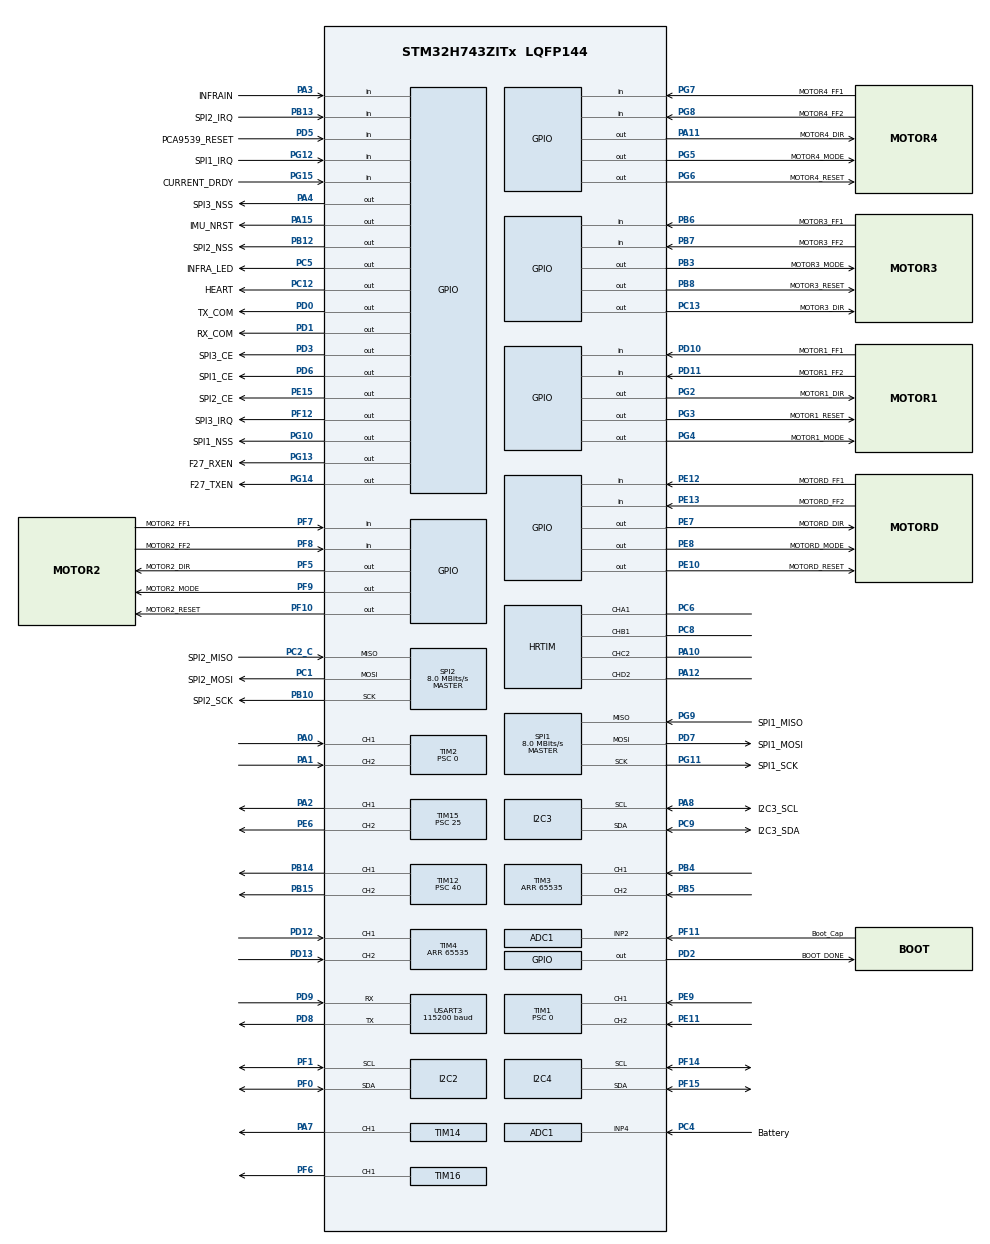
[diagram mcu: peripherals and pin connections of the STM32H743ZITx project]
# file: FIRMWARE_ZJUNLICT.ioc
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ADC1.Channel-0\#ChannelRegularConversion=ADC_CHANNEL_4
ADC1.Channel-1\#ChannelRegularConversion=ADC_CHANNEL_2
ADC1.ClockPrescaler=ADC_CLOCK_ASYNC_DIV2
ADC1.ContinuousConvMode=ENABLE
ADC1.ConversionDataManagement=ADC_CONVERSIONDATA_DMA_CIRCULAR
ADC1.EOCSelection=ADC_EOC_SINGLE_CONV
ADC1.LeftBitShift=ADC_LEFTBITSHIFT_NONE
ADC1.NbrOfConversion=2
ADC1.NbrOfConversionFlag=1
ADC1.OffsetNumber-1\#ChannelRegularConversion=ADC_OFFSET_NONE
ADC1.Overrun=ADC_OVR_DATA_OVERWRITTEN
ADC1.Rank-1\#ChannelRegularConversion=2
ADC1.SamplingTime-0\#ChannelRegularConversion=ADC_SAMPLETIME_2CYCLES_5
ADC1.SamplingTime-1\#ChannelRegularConversion=ADC_SAMPLETIME_1CYCLE_5
ADC1.master=1
CORTEX_M7.CPU_DCache=Disabled
CORTEX_M7.CPU_ICache=Enabled
Dma.ADC1.3.Direction=DMA_PERIPH_TO_MEMORY
Dma.ADC1.3.EventEnable=DISABLE
Dma.ADC1.3.FIFOMode=DMA_FIFOMODE_DISABLE
Dma.ADC1.3.Instance=DMA1_Stream2
Dma.ADC1.3.MemDataAlignment=DMA_MDATAALIGN_HALFWORD
Dma.ADC1.3.MemInc=DMA_MINC_ENABLE
Dma.ADC1.3.Mode=DMA_CIRCULAR
Dma.ADC1.3.PeriphDataAlignment=DMA_PDATAALIGN_HALFWORD
Dma.ADC1.3.PeriphInc=DMA_PINC_DISABLE
Dma.ADC1.3.Polarity=HAL_DMAMUX_REQ_GEN_RISING
Dma.ADC1.3.Priority=DMA_PRIORITY_MEDIUM
Dma.ADC1.3.RequestNumber=1
Dma.ADC1.3.SignalID=HAL_DMAMUX1_REQ_GEN_TIM12_TRGO
Dma.ADC1.3.SyncEnable=DISABLE
Dma.ADC1.3.SyncPolarity=HAL_DMAMUX_SYNC_NO_EVENT
Dma.ADC1.3.SyncRequestNumber=1
Dma.ADC1.3.SyncSignalID=NONE
Dma.I2C3_RX.1.Direction=DMA_PERIPH_TO_MEMORY
Dma.I2C3_RX.1.EventEnable=DISABLE
Dma.I2C3_RX.1.FIFOMode=DMA_FIFOMODE_ENABLE
Dma.I2C3_RX.1.FIFOThreshold=DMA_FIFO_THRESHOLD_FULL
Dma.I2C3_RX.1.Instance=DMA1_Stream1
Dma.I2C3_RX.1.MemBurst=DMA_MBURST_SINGLE
Dma.I2C3_RX.1.MemDataAlignment=DMA_MDATAALIGN_BYTE
Dma.I2C3_RX.1.MemInc=DMA_MINC_ENABLE
Dma.I2C3_RX.1.Mode=DMA_NORMAL
Dma.I2C3_RX.1.PeriphBurst=DMA_PBURST_SINGLE
Dma.I2C3_RX.1.PeriphDataAlignment=DMA_PDATAALIGN_BYTE
Dma.I2C3_RX.1.PeriphInc=DMA_PINC_DISABLE
Dma.I2C3_RX.1.Polarity=HAL_DMAMUX_REQ_GEN_RISING
Dma.I2C3_RX.1.Priority=DMA_PRIORITY_LOW
Dma.I2C3_RX.1.RequestNumber=1
Dma.I2C3_RX.1.SignalID=HAL_DMAMUX1_REQ_GEN_TIM12_TRGO
Dma.I2C3_RX.1.SyncEnable=DISABLE
Dma.I2C3_RX.1.SyncPolarity=HAL_DMAMUX_SYNC_NO_EVENT
Dma.I2C3_RX.1.SyncRequestNumber=1
Dma.I2C3_RX.1.SyncSignalID=NONE
Dma.I2C3_TX.0.Direction=DMA_MEMORY_TO_PERIPH
Dma.I2C3_TX.0.EventEnable=DISABLE
Dma.I2C3_TX.0.FIFOMode=DMA_FIFOMODE_ENABLE
Dma.I2C3_TX.0.FIFOThreshold=DMA_FIFO_THRESHOLD_FULL
Dma.I2C3_TX.0.Instance=DMA1_Stream0
Dma.I2C3_TX.0.MemBurst=DMA_MBURST_SINGLE
Dma.I2C3_TX.0.MemDataAlignment=DMA_MDATAALIGN_BYTE
Dma.I2C3_TX.0.MemInc=DMA_MINC_ENABLE
Dma.I2C3_TX.0.Mode=DMA_NORMAL
Dma.I2C3_TX.0.PeriphBurst=DMA_PBURST_SINGLE
Dma.I2C3_TX.0.PeriphDataAlignment=DMA_PDATAALIGN_BYTE
Dma.I2C3_TX.0.PeriphInc=DMA_PINC_DISABLE
Dma.I2C3_TX.0.Polarity=HAL_DMAMUX_REQ_GEN_RISING
Dma.I2C3_TX.0.Priority=DMA_PRIORITY_LOW
Dma.I2C3_TX.0.RequestNumber=1
Dma.I2C3_TX.0.SignalID=HAL_DMAMUX1_REQ_GEN_TIM12_TRGO
Dma.I2C3_TX.0.SyncEnable=DISABLE
Dma.I2C3_TX.0.SyncPolarity=HAL_DMAMUX_SYNC_NO_EVENT
Dma.I2C3_TX.0.SyncRequestNumber=1
Dma.I2C3_TX.0.SyncSignalID=NONE
Dma.Request0=I2C3_TX
Dma.Request1=I2C3_RX
Dma.Request2=USART3_TX
Dma.Request3=ADC1
Dma.Request4=SPI1_RX
Dma.Request5=SPI1_TX
Dma.Request6=SPI2_RX
Dma.Request7=SPI2_TX
Dma.SPI1_RX.4.Direction=DMA_PERIPH_TO_MEMORY
Dma.SPI1_RX.4.EventEnable=DISABLE
Dma.SPI1_RX.4.FIFOMode=DMA_FIFOMODE_ENABLE
Dma.SPI1_RX.4.FIFOThreshold=DMA_FIFO_THRESHOLD_FULL
Dma.SPI1_RX.4.Instance=DMA2_Stream0
Dma.SPI1_RX.4.MemBurst=DMA_MBURST_SINGLE
Dma.SPI1_RX.4.MemDataAlignment=DMA_MDATAALIGN_BYTE
Dma.SPI1_RX.4.MemInc=DMA_MINC_ENABLE
Dma.SPI1_RX.4.Mode=DMA_NORMAL
Dma.SPI1_RX.4.PeriphBurst=DMA_PBURST_SINGLE
Dma.SPI1_RX.4.PeriphDataAlignment=DMA_PDATAALIGN_BYTE
Dma.SPI1_RX.4.PeriphInc=DMA_PINC_DISABLE
Dma.SPI1_RX.4.Polarity=HAL_DMAMUX_REQ_GEN_RISING
Dma.SPI1_RX.4.Priority=DMA_PRIORITY_MEDIUM
Dma.SPI1_RX.4.RequestNumber=1
Dma.SPI1_RX.4.SignalID=HAL_DMAMUX1_REQ_GEN_TIM12_TRGO
Dma.SPI1_RX.4.SyncEnable=DISABLE
Dma.SPI1_RX.4.SyncPolarity=HAL_DMAMUX_SYNC_NO_EVENT
Dma.SPI1_RX.4.SyncRequestNumber=1
Dma.SPI1_RX.4.SyncSignalID=NONE
Dma.SPI1_TX.5.Direction=DMA_MEMORY_TO_PERIPH
Dma.SPI1_TX.5.EventEnable=DISABLE
Dma.SPI1_TX.5.FIFOMode=DMA_FIFOMODE_ENABLE
Dma.SPI1_TX.5.FIFOThreshold=DMA_FIFO_THRESHOLD_FULL
Dma.SPI1_TX.5.Instance=DMA2_Stream1
Dma.SPI1_TX.5.MemBurst=DMA_MBURST_SINGLE
Dma.SPI1_TX.5.MemDataAlignment=DMA_MDATAALIGN_BYTE
Dma.SPI1_TX.5.MemInc=DMA_MINC_ENABLE
Dma.SPI1_TX.5.Mode=DMA_NORMAL
Dma.SPI1_TX.5.PeriphBurst=DMA_PBURST_SINGLE
Dma.SPI1_TX.5.PeriphDataAlignment=DMA_PDATAALIGN_BYTE
Dma.SPI1_TX.5.PeriphInc=DMA_PINC_DISABLE
Dma.SPI1_TX.5.Polarity=HAL_DMAMUX_REQ_GEN_RISING
Dma.SPI1_TX.5.Priority=DMA_PRIORITY_MEDIUM
Dma.SPI1_TX.5.RequestNumber=1
Dma.SPI1_TX.5.SignalID=HAL_DMAMUX1_REQ_GEN_TIM12_TRGO
Dma.SPI1_TX.5.SyncEnable=DISABLE
Dma.SPI1_TX.5.SyncPolarity=HAL_DMAMUX_SYNC_NO_EVENT
Dma.SPI1_TX.5.SyncRequestNumber=1
Dma.SPI1_TX.5.SyncSignalID=NONE
Dma.SPI2_RX.6.Direction=DMA_PERIPH_TO_MEMORY
Dma.SPI2_RX.6.EventEnable=DISABLE
Dma.SPI2_RX.6.FIFOMode=DMA_FIFOMODE_ENABLE
Dma.SPI2_RX.6.FIFOThreshold=DMA_FIFO_THRESHOLD_FULL
Dma.SPI2_RX.6.Instance=DMA1_Stream4
Dma.SPI2_RX.6.MemBurst=DMA_MBURST_SINGLE
Dma.SPI2_RX.6.MemDataAlignment=DMA_MDATAALIGN_BYTE
Dma.SPI2_RX.6.MemInc=DMA_MINC_ENABLE
Dma.SPI2_RX.6.Mode=DMA_NORMAL
Dma.SPI2_RX.6.PeriphBurst=DMA_PBURST_SINGLE
Dma.SPI2_RX.6.PeriphDataAlignment=DMA_PDATAALIGN_BYTE
Dma.SPI2_RX.6.PeriphInc=DMA_PINC_DISABLE
Dma.SPI2_RX.6.Polarity=HAL_DMAMUX_REQ_GEN_RISING
Dma.SPI2_RX.6.Priority=DMA_PRIORITY_LOW
Dma.SPI2_RX.6.RequestNumber=1
Dma.SPI2_RX.6.SignalID=HAL_DMAMUX1_REQ_GEN_TIM12_TRGO
Dma.SPI2_RX.6.SyncEnable=DISABLE
Dma.SPI2_RX.6.SyncPolarity=HAL_DMAMUX_SYNC_NO_EVENT
Dma.SPI2_RX.6.SyncRequestNumber=1
Dma.SPI2_RX.6.SyncSignalID=HAL_DMAMUX1_SYNC_TIM12_TRGO
Dma.SPI2_TX.7.Direction=DMA_MEMORY_TO_PERIPH
Dma.SPI2_TX.7.EventEnable=DISABLE
Dma.SPI2_TX.7.FIFOMode=DMA_FIFOMODE_ENABLE
Dma.SPI2_TX.7.FIFOThreshold=DMA_FIFO_THRESHOLD_FULL
Dma.SPI2_TX.7.Instance=DMA1_Stream5
Dma.SPI2_TX.7.MemBurst=DMA_MBURST_SINGLE
Dma.SPI2_TX.7.MemDataAlignment=DMA_MDATAALIGN_BYTE
Dma.SPI2_TX.7.MemInc=DMA_MINC_ENABLE
Dma.SPI2_TX.7.Mode=DMA_NORMAL
Dma.SPI2_TX.7.PeriphBurst=DMA_PBURST_SINGLE
Dma.SPI2_TX.7.PeriphDataAlignment=DMA_PDATAALIGN_BYTE
Dma.SPI2_TX.7.PeriphInc=DMA_PINC_DISABLE
Dma.SPI2_TX.7.Polarity=HAL_DMAMUX_REQ_GEN_RISING
Dma.SPI2_TX.7.Priority=DMA_PRIORITY_LOW
Dma.SPI2_TX.7.RequestNumber=1
Dma.SPI2_TX.7.SignalID=HAL_DMAMUX1_REQ_GEN_TIM12_TRGO
Dma.SPI2_TX.7.SyncEnable=DISABLE
Dma.SPI2_TX.7.SyncPolarity=HAL_DMAMUX_SYNC_NO_EVENT
Dma.SPI2_TX.7.SyncRequestNumber=1
Dma.SPI2_TX.7.SyncSignalID=HAL_DMAMUX1_SYNC_TIM12_TRGO
Dma.USART3_TX.2.Direction=DMA_MEMORY_TO_PERIPH
Dma.USART3_TX.2.EventEnable=DISABLE
Dma.USART3_TX.2.FIFOMode=DMA_FIFOMODE_ENABLE
Dma.USART3_TX.2.FIFOThreshold=DMA_FIFO_THRESHOLD_FULL
Dma.USART3_TX.2.Instance=DMA1_Stream3
Dma.USART3_TX.2.MemBurst=DMA_MBURST_SINGLE
Dma.USART3_TX.2.MemDataAlignment=DMA_MDATAALIGN_BYTE
Dma.USART3_TX.2.MemInc=DMA_MINC_ENABLE
Dma.USART3_TX.2.Mode=DMA_NORMAL
Dma.USART3_TX.2.PeriphBurst=DMA_PBURST_SINGLE
Dma.USART3_TX.2.PeriphDataAlignment=DMA_PDATAALIGN_BYTE
Dma.USART3_TX.2.PeriphInc=DMA_PINC_DISABLE
Dma.USART3_TX.2.Polarity=HAL_DMAMUX_REQ_GEN_RISING
Dma.USART3_TX.2.Priority=DMA_PRIORITY_HIGH
Dma.USART3_TX.2.RequestNumber=1
Dma.USART3_TX.2.SignalID=HAL_DMAMUX1_REQ_GEN_TIM12_TRGO
Dma.USART3_TX.2.SyncEnable=DISABLE
Dma.USART3_TX.2.SyncPolarity=HAL_DMAMUX_SYNC_NO_EVENT
Dma.USART3_TX.2.SyncRequestNumber=1
Dma.USART3_TX.2.SyncSignalID=NONE
HRTIM.CompareUnit1-Output_TA1=HRTIM_COMPAREUNIT_1
HRTIM.CompareUnit1-Output_TB1=HRTIM_COMPAREUNIT_1
HRTIM.CompareUnit1-Output_TC2=HRTIM_COMPAREUNIT_1
HRTIM.CompareUnit1-Output_TD2=HRTIM_COMPAREUNIT_1
HRTIM.CompareValue1-Output_TA1=3
HRTIM.CompareValue1-Output_TB1=3
HRTIM.CompareValue1-Output_TC2=3
HRTIM.CompareValue1-Output_TD2=3
HRTIM.Configuration_TC=Waveform
HRTIM.HalfModeEnable-Output_TC2=HRTIM_HALFMODE_DISABLED
HRTIM.NumberResetSource1-Output_TA1=1
HRTIM.NumberResetSource1-Output_TB1=1
HRTIM.NumberResetSource2-Output_TC2=1
HRTIM.NumberResetSource2-Output_TD2=1
HRTIM.NumberSetSource1-Output_TA1=1
HRTIM.NumberSetSource1-Output_TB1=1
HRTIM.NumberSetSource2-Output_TC2=1
HRTIM.NumberSetSource2-Output_TD2=1
HRTIM.Periode_TA=8000
HRTIM.Periode_TB=8000
HRTIM.Periode_TC=8000
HRTIM.Periode_TD=8000
HRTIM.PrescalerRatio_TC=HRTIM_PRESCALERRATIO_DIV1
HRTIM.RepetitionCounter-Output_TC2=0
HRTIM.ResetOutput1_Source1-Output_TA1=HRTIM_OUTPUTRESET_TIMCMP1
HRTIM.ResetOutput1_Source1-Output_TB1=HRTIM_OUTPUTRESET_TIMCMP1
HRTIM.ResetOutput2_Source1-Output_TC2=HRTIM_OUTPUTRESET_TIMCMP1
HRTIM.ResetOutput2_Source1-Output_TD2=HRTIM_OUTPUTRESET_TIMCMP1
HRTIM.SetOutput1_Source1-Output_TA1=HRTIM_OUTPUTSET_TIMPER
HRTIM.SetOutput1_Source1-Output_TB1=HRTIM_OUTPUTSET_TIMPER
HRTIM.SetOutput2_Source1-Output_TC2=HRTIM_OUTPUTSET_TIMPER
HRTIM.SetOutput2_Source1-Output_TD2=HRTIM_OUTPUTSET_TIMPER
I2C2.Timing=0x10C0ECFF
I2C3.Timing=0x10C0ECFF
I2C4.Timing=0x10C0ECFF
Mcu.Family=STM32H7
Mcu.Name=STM32H743ZITx
Mcu.Package=LQFP144
NVIC.ADC_IRQn=true\:0\:0\:false\:false\:true\:true\:true
NVIC.DMA1_Stream0_IRQn=true\:0\:0\:false\:false\:true\:false\:true
NVIC.DMA1_Stream1_IRQn=true\:0\:0\:false\:false\:true\:false\:true
NVIC.DMA1_Stream2_IRQn=true\:0\:0\:false\:false\:true\:false\:true
NVIC.DMA1_Stream3_IRQn=true\:0\:0\:false\:false\:true\:false\:true
NVIC.DMA1_Stream4_IRQn=true\:0\:0\:false\:false\:true\:false\:true
NVIC.DMA1_Stream5_IRQn=true\:0\:0\:false\:false\:true\:false\:true
NVIC.DMA2_Stream0_IRQn=true\:0\:0\:false\:false\:true\:false\:true
NVIC.DMA2_Stream1_IRQn=true\:0\:0\:false\:false\:true\:false\:true
NVIC.PriorityGroup=NVIC_PRIORITYGROUP_4
NVIC.SPI1_IRQn=true\:1\:0\:true\:false\:true\:false\:true
NVIC.SPI2_IRQn=true\:0\:0\:false\:false\:true\:false\:true
NVIC.TIM5_IRQn=true\:2\:0\:true\:false\:true\:true\:true
NVIC.USART3_IRQn=true\:0\:0\:false\:false\:true\:true\:true
PA0.Signal=S_TIM2_CH1
PA1.Signal=S_TIM2_CH2
PA10.Mode=Output_TC2
PA10.Signal=HRTIM_CHC2
PA11.GPIO_Label=MOTOR4_DIR
PA11.GPIO_ModeDefaultOutputPP=GPIO_MODE_OUTPUT_PP
PA11.GPIO_PuPd=GPIO_NOPULL
PA11.GPIO_Speed=GPIO_SPEED_FREQ_LOW
PA11.PinState=GPIO_PIN_RESET
PA11.Signal=GPIO_Output
PA12.Mode=Output_TD2
PA12.Signal=HRTIM_CHD2
PA15\ (JTDI).GPIO_Label=IMU_NRST
PA15\ (JTDI).Signal=GPIO_Output
PA2.Signal=S_TIM15_CH1
PA3.GPIO_Label=INFRAIN
PA3.GPIO_Mode=GPIO_MODE_INPUT
PA3.GPIO_PuPd=GPIO_NOPULL
PA3.Signal=GPIO_Input
PA4.GPIO_Label=SPI3_NSS
PA4.Signal=GPIO_Output
PA7.Signal=S_TIM14_CH1
PA8.GPIO_Label=I2C3_SCL
PA8.GPIO_Mode=GPIO_MODE_AF_OD
PA8.GPIO_PuPd=GPIO_NOPULL
PA8.GPIO_Speed=GPIO_SPEED_FREQ_LOW
PA8.Mode=I2C
PA8.Signal=I2C3_SCL
PB10.GPIO_Label=SPI2_SCK
PB10.Mode=Full_Duplex_Master
PB10.Signal=SPI2_SCK
PB12.GPIO_Label=SPI2_NSS
PB12.GPIO_ModeDefaultOutputPP=GPIO_MODE_OUTPUT_PP
PB12.GPIO_PuPd=GPIO_NOPULL
PB12.GPIO_Speed=GPIO_SPEED_FREQ_LOW
PB12.PinState=GPIO_PIN_RESET
PB12.Signal=GPIO_Output
PB13.GPIO_Label=SPI2_IRQ
PB13.GPIO_Mode=GPIO_MODE_INPUT
PB13.GPIO_PuPd=GPIO_NOPULL
PB13.Signal=GPIO_Input
PB14.Signal=S_TIM12_CH1
PB15.Signal=S_TIM12_CH2
PB2.Signal=SPI3_MOSI
PB3\ (JTDO/TRACESWO).GPIO_Label=MOTOR3_MODE
PB3\ (JTDO/TRACESWO).Signal=GPIO_Output
PB4\ (NJTRST).Signal=S_TIM3_CH1
PB5.Signal=S_TIM3_CH2
PB6.GPIO_Label=MOTOR3_FF1
PB6.GPIO_Mode=GPIO_MODE_INPUT
PB6.GPIO_PuPd=GPIO_NOPULL
PB6.Signal=GPIO_Input
PB7.GPIO_Label=MOTOR3_FF2
PB7.GPIO_Mode=GPIO_MODE_INPUT
PB7.GPIO_PuPd=GPIO_NOPULL
PB7.Signal=GPIO_Input
PB8.GPIO_FM8=__NULL
PB8.GPIO_Label=MOTOR3_RESET
PB8.GPIO_ModeDefaultOutputPP=GPIO_MODE_OUTPUT_PP
PB8.GPIO_PuPd=GPIO_NOPULL
PB8.GPIO_Speed=GPIO_SPEED_FREQ_LOW
PB8.PinState=GPIO_PIN_RESET
PB8.Signal=GPIO_Output
PC1.GPIO_Label=SPI2_MOSI
PC1.Mode=Full_Duplex_Master
PC1.Signal=SPI2_MOSI
PC10.Signal=SPI3_SCK
PC11.Signal=SPI3_MISO
PC12.GPIO_Label=HEART 
PC12.GPIO_ModeDefaultOutputPP=GPIO_MODE_OUTPUT_PP
PC12.GPIO_PuPd=GPIO_NOPULL
PC12.GPIO_Speed=GPIO_SPEED_FREQ_LOW
PC12.PinState=GPIO_PIN_RESET
PC12.Signal=GPIO_Output
PC13.GPIO_Label=MOTOR3_DIR
PC13.GPIO_ModeDefaultOutputPP=GPIO_MODE_OUTPUT_PP
PC13.GPIO_PuPd=GPIO_NOPULL
PC13.GPIO_Speed=GPIO_SPEED_FREQ_LOW
PC13.PinState=GPIO_PIN_RESET
PC13.Signal=GPIO_Output
PC2_C.GPIO_Label=SPI2_MISO
PC2_C.Mode=Full_Duplex_Master
PC2_C.Signal=SPI2_MISO
PC4.GPIO_Label=Battery
PC4.GPIO_Mode=GPIO_MODE_ANALOG
PC4.GPIO_PuPd=GPIO_NOPULL
PC4.Signal=ADCx_INP4
PC5.GPIO_Label=INFRA_LED
PC5.GPIO_ModeDefaultOutputPP=GPIO_MODE_OUTPUT_PP
PC5.GPIO_PuPd=GPIO_NOPULL
PC5.GPIO_Speed=GPIO_SPEED_FREQ_LOW
PC5.PinState=GPIO_PIN_RESET
PC5.Signal=GPIO_Output
PC6.Mode=Output_TA1
PC6.Signal=HRTIM_CHA1
PC8.Mode=Output_TB1
PC8.Signal=HRTIM_CHB1
PC9.GPIO_Label=I2C3_SDA
PC9.GPIO_Mode=GPIO_MODE_AF_OD
PC9.GPIO_PuPd=GPIO_NOPULL
PC9.GPIO_Speed=GPIO_SPEED_FREQ_LOW
PC9.Mode=I2C
PC9.Signal=I2C3_SDA
PD0.GPIO_Label=TX_COM
PD0.Signal=GPIO_Output
PD1.GPIO_Label=RX_COM
PD1.Signal=GPIO_Output
PD10.GPIO_Label=MOTOR1_FF1
PD10.GPIO_Mode=GPIO_MODE_INPUT
PD10.GPIO_PuPd=GPIO_NOPULL
PD10.Signal=GPIO_Input
PD11.GPIO_Label=MOTOR1_FF2
PD11.GPIO_Mode=GPIO_MODE_INPUT
PD11.GPIO_PuPd=GPIO_NOPULL
PD11.Signal=GPIO_Input
PD12.Signal=S_TIM4_CH1
PD13.Signal=S_TIM4_CH2
PD14.Signal=UART8_CTS
PD15.Signal=UART8_RTS
PD2.GPIO_Label=BOOT_DONE
PD2.Signal=GPIO_Output
PD3.GPIO_Label=SPI3_CE
PD3.Signal=GPIO_Output
PD5.GPIO_Label=PCA9539_RESET
PD5.Signal=GPIO_Input
PD6.GPIO_Label=SPI1_CE
PD6.GPIO_ModeDefaultOutputPP=GPIO_MODE_OUTPUT_PP
PD6.GPIO_PuPd=GPIO_NOPULL
PD6.GPIO_Speed=GPIO_SPEED_FREQ_LOW
PD6.PinState=GPIO_PIN_RESET
PD6.Signal=GPIO_Output
PD7.GPIO_Label=SPI1_MOSI
PD7.Mode=Full_Duplex_Master
PD7.Signal=SPI1_MOSI
PD8.Mode=Asynchronous
PD8.Signal=USART3_TX
PD9.Mode=Asynchronous
PD9.Signal=USART3_RX
PE10.GPIO_Label=MOTORD_RESET
PE10.GPIO_ModeDefaultOutputPP=GPIO_MODE_OUTPUT_PP
PE10.GPIO_PuPd=GPIO_NOPULL
PE10.GPIO_Speed=GPIO_SPEED_FREQ_LOW
PE10.PinState=GPIO_PIN_RESET
PE10.Signal=GPIO_Output
PE11.Signal=S_TIM1_CH2
PE12.GPIO_Label=MOTORD_FF1
PE12.GPIO_Mode=GPIO_MODE_INPUT
PE12.GPIO_PuPd=GPIO_NOPULL
PE12.Signal=GPIO_Input
PE13.GPIO_Label=MOTORD_FF2
PE13.GPIO_Mode=GPIO_MODE_INPUT
PE13.GPIO_PuPd=GPIO_NOPULL
PE13.Signal=GPIO_Input
PE15.GPIO_Label=SPI2_CE
PE15.GPIO_ModeDefaultOutputPP=GPIO_MODE_OUTPUT_PP
PE15.GPIO_PuPd=GPIO_NOPULL
PE15.GPIO_Speed=GPIO_SPEED_FREQ_LOW
PE15.PinState=GPIO_PIN_RESET
PE15.Signal=GPIO_Output
PE6.Signal=S_TIM15_CH2
PE7.GPIO_Label=MOTORD_DIR
PE7.GPIO_ModeDefaultOutputPP=GPIO_MODE_OUTPUT_PP
PE7.GPIO_PuPd=GPIO_NOPULL
PE7.GPIO_Speed=GPIO_SPEED_FREQ_LOW
PE7.PinState=GPIO_PIN_RESET
PE7.Signal=GPIO_Output
PE8.GPIO_Label=MOTORD_MODE
PE8.GPIO_ModeDefaultOutputPP=GPIO_MODE_OUTPUT_PP
PE8.GPIO_PuPd=GPIO_NOPULL
PE8.GPIO_Speed=GPIO_SPEED_FREQ_LOW
PE8.PinState=GPIO_PIN_RESET
PE8.Signal=GPIO_Output
PE9.Signal=S_TIM1_CH1
PF0.Mode=I2C
PF0.Signal=I2C2_SDA
PF1.Mode=I2C
PF1.Signal=I2C2_SCL
PF10.GPIO_Label=MOTOR2_RESET 
PF10.GPIO_ModeDefaultOutputPP=GPIO_MODE_OUTPUT_PP
PF10.GPIO_PuPd=GPIO_NOPULL
PF10.GPIO_Speed=GPIO_SPEED_FREQ_LOW
PF10.PinState=GPIO_PIN_RESET
PF10.Signal=GPIO_Output
PF11.GPIO_Label=Boot_Cap
PF11.GPIO_Mode=GPIO_MODE_ANALOG
PF11.GPIO_PuPd=GPIO_NOPULL
PF11.Mode=IN2-Single-Ended
PF11.Signal=ADC1_INP2
PF12.GPIO_Label=SPI3_IRQ
PF12.Signal=GPIO_Output
PF14.Mode=I2C
PF14.Signal=I2C4_SCL
PF15.Mode=I2C
PF15.Signal=I2C4_SDA
PF5.GPIO_Label=MOTOR2_DIR 
PF5.GPIO_ModeDefaultOutputPP=GPIO_MODE_OUTPUT_PP
PF5.GPIO_PuPd=GPIO_NOPULL
PF5.GPIO_Speed=GPIO_SPEED_FREQ_LOW
PF5.PinState=GPIO_PIN_RESET
PF5.Signal=GPIO_Output
PF6.Signal=S_TIM16_CH1
PF7.GPIO_Label=MOTOR2_FF1
PF7.GPIO_Mode=GPIO_MODE_INPUT
PF7.GPIO_PuPd=GPIO_NOPULL
PF7.Signal=GPIO_Input
PF8.GPIO_Label=MOTOR2_FF2
PF8.GPIO_Mode=GPIO_MODE_INPUT
PF8.GPIO_PuPd=GPIO_NOPULL
PF8.Signal=GPIO_Input
PF9.GPIO_Label=MOTOR2_MODE 
PF9.GPIO_ModeDefaultOutputPP=GPIO_MODE_OUTPUT_PP
PF9.GPIO_PuPd=GPIO_NOPULL
PF9.GPIO_Speed=GPIO_SPEED_FREQ_LOW
PF9.PinState=GPIO_PIN_RESET
PF9.Signal=GPIO_Output
PG10.GPIO_Label=SPI1_NSS
PG10.GPIO_ModeDefaultOutputPP=GPIO_MODE_OUTPUT_PP
PG10.GPIO_PuPd=GPIO_NOPULL
PG10.GPIO_Speed=GPIO_SPEED_FREQ_LOW
PG10.PinState=GPIO_PIN_RESET
PG10.Signal=GPIO_Output
PG11.GPIO_Label=SPI1_SCK
PG11.Mode=Full_Duplex_Master
PG11.Signal=SPI1_SCK
PG12.GPIO_Label=SPI1_IRQ
PG12.GPIO_Mode=GPIO_MODE_INPUT
PG12.GPIO_PuPd=GPIO_NOPULL
PG12.Signal=GPIO_Input
PG13.GPIO_Label=F27_RXEN
PG13.Signal=GPIO_Output
PG14.GPIO_Label=F27_TXEN
PG14.Signal=GPIO_Output
PG15.GPIO_Label=CURRENT_DRDY
PG15.Signal=GPIO_Input
PG2.GPIO_Label=MOTOR1_DIR
PG2.GPIO_ModeDefaultOutputPP=GPIO_MODE_OUTPUT_PP
PG2.GPIO_PuPd=GPIO_NOPULL
PG2.GPIO_Speed=GPIO_SPEED_FREQ_LOW
PG2.PinState=GPIO_PIN_RESET
PG2.Signal=GPIO_Output
PG3.GPIO_Label=MOTOR1_RESET
PG3.Signal=GPIO_Output
PG4.GPIO_Label=MOTOR1_MODE
PG4.Signal=GPIO_Output
PG5.GPIO_Label=MOTOR4_MODE
PG5.GPIO_ModeDefaultOutputPP=GPIO_MODE_OUTPUT_PP
PG5.GPIO_PuPd=GPIO_NOPULL
PG5.GPIO_Speed=GPIO_SPEED_FREQ_LOW
PG5.PinState=GPIO_PIN_RESET
PG5.Signal=GPIO_Output
PG6.GPIO_Label=MOTOR4_RESET
PG6.GPIO_ModeDefaultOutputPP=GPIO_MODE_OUTPUT_PP
PG6.GPIO_PuPd=GPIO_NOPULL
PG6.GPIO_Speed=GPIO_SPEED_FREQ_LOW
PG6.PinState=GPIO_PIN_RESET
PG6.Signal=GPIO_Output
PG7.GPIO_Label=MOTOR4_FF1
PG7.GPIO_Mode=GPIO_MODE_INPUT
PG7.GPIO_PuPd=GPIO_NOPULL
PG7.Signal=GPIO_Input
PG8.GPIO_Label=MOTOR4_FF2
PG8.GPIO_Mode=GPIO_MODE_INPUT
PG8.GPIO_PuPd=GPIO_NOPULL
PG8.Signal=GPIO_Input
PG9.GPIO_Label=SPI1_MISO
PG9.Mode=Full_Duplex_Master
PG9.Signal=SPI1_MISO
PH0-OSC_IN\ (PH0).Mode=HSE-External-Oscillator
PH0-OSC_IN\ (PH0).Signal=RCC_OSC_IN
PH1-OSC_OUT\ (PH1).Mode=HSE-External-Oscillator
PH1-OSC_OUT\ (PH1).Signal=RCC_OSC_OUT
ProjectManager.HeapSize=0x200
ProjectManager.StackSize=0x400
ProjectManager.TargetToolchain=MDK-ARM V5
RCC.ADCCLockSelection=RCC_ADCCLKSOURCE_CLKP
RCC.ADCFreq_Value=64000000
RCC.APB1Freq_Value=100000000
RCC.APB2Freq_Value=100000000
RCC.APB3Freq_Value=100000000
RCC.APB4Freq_Value=100000000
RCC.CortexFreq_Value=400000000
RCC.D1PPRE=RCC_APB3_DIV2
RCC.D2PPRE1=RCC_APB1_DIV2
RCC.D2PPRE2=RCC_APB2_DIV2
RCC.D3PPRE=RCC_APB4_DIV2
RCC.DIVM1=1
RCC.DIVM2=1
RCC.DIVN1=100
RCC.DIVN2=32
RCC.DIVP2=4
RCC.DIVR1=4
RCC.HCLKFreq_Value=200000000
RCC.HPRE=RCC_HCLK_DIV2
RCC.HRTIMCLockSelection=RCC_HRTIM1CLK_CPUCLK
RCC.HSE_VALUE=8000000
RCC.PLL1_VCI_Range-AdvancedSettings=RCC_PLL1VCIRANGE_0
RCC.PLL2_VCO_SEL-AdvancedSettings=RCC_PLL2VCOMEDIUM
RCC.PLL3_VCO_SEL-AdvancedSettings=RCC_PLL3VCOMEDIUM
RCC.PLLSourceVirtual=RCC_PLLSOURCE_HSE
RCC.PWR_Regulator_Voltage_Scale=PWR_REGULATOR_VOLTAGE_SCALE1
RCC.SPI123CLockSelection=RCC_SPI123CLKSOURCE_PLL2
RCC.SYSCLKFreq_VALUE=400000000
RCC.SYSCLKSource=RCC_SYSCLKSOURCE_PLLCLK
RCC.USBFreq_Value=400000000
SH.ADCx_INP4.0=ADC1_INP4,IN4-Single-Ended
SH.S_TIM12_CH1.0=TIM12_CH1,PWM Generation1 CH1
SH.S_TIM12_CH2.0=TIM12_CH2,PWM Generation2 CH2
SH.S_TIM14_CH1.0=TIM14_CH1,PWM Generation1 CH1
SH.S_TIM15_CH1.0=TIM15_CH1,PWM Generation1 CH1
SH.S_TIM15_CH2.0=TIM15_CH2,PWM Generation2 CH2
SH.S_TIM16_CH1.0=TIM16_CH1,PWM Generation1 CH1
SH.S_TIM1_CH1.0=TIM1_CH1,Encoder_Interface
SH.S_TIM1_CH2.0=TIM1_CH2,Encoder_Interface
SH.S_TIM2_CH1.0=TIM2_CH1,Encoder_Interface
SH.S_TIM2_CH2.0=TIM2_CH2,Encoder_Interface
SH.S_TIM3_CH1.0=TIM3_CH1,Encoder_Interface
SH.S_TIM3_CH2.0=TIM3_CH2,Encoder_Interface
SH.S_TIM4_CH1.0=TIM4_CH1,Encoder_Interface
SH.S_TIM4_CH2.0=TIM4_CH2,Encoder_Interface
SPI1.BaudRatePrescaler=SPI_BAUDRATEPRESCALER_8
SPI1.CalculateBaudRate=8.0 MBits/s
SPI1.DataSize=SPI_DATASIZE_8BIT
SPI1.Direction=SPI_DIRECTION_2LINES
SPI1.Mode=SPI_MODE_MASTER
SPI1.NSSPMode=SPI_NSS_PULSE_DISABLE
SPI1.VirtualType=VM_MASTER
SPI2.BaudRatePrescaler=SPI_BAUDRATEPRESCALER_8
SPI2.CalculateBaudRate=8.0 MBits/s
SPI2.DataSize=SPI_DATASIZE_8BIT
SPI2.Direction=SPI_DIRECTION_2LINES
SPI2.Mode=SPI_MODE_MASTER
SPI2.NSSPMode=SPI_NSS_PULSE_DISABLE
SPI2.VirtualType=VM_MASTER
TIM1.EncoderMode=TIM_ENCODERMODE_TI12
TIM1.Period=65535
TIM1.Prescaler=0
TIM12.AutoReloadPreload=TIM_AUTORELOAD_PRELOAD_DISABLE
TIM12.Channel-PWM\ Generation1\ CH1=TIM_CHANNEL_1
TIM12.Channel-PWM\ Generation2\ CH2=TIM_CHANNEL_2
TIM12.OCFastMode_PWM-PWM\ Generation1\ CH1=TIM_OCFAST_DISABLE
TIM12.OCFastMode_PWM-PWM\ Generation2\ CH2=TIM_OCFAST_DISABLE
TIM12.OCMode_PWM-PWM\ Generation1\ CH1=TIM_OCMODE_PWM2
TIM12.OCMode_PWM-PWM\ Generation2\ CH2=TIM_OCMODE_PWM2
TIM12.OCPolarity_1=TIM_OCPOLARITY_HIGH
TIM12.OCPolarity_2=TIM_OCPOLARITY_HIGH
TIM12.Period=65000
TIM12.Prescaler=40
TIM12.Pulse-PWM\ Generation1\ CH1=65000
TIM12.Pulse-PWM\ Generation2\ CH2=65000
TIM14.Channel=TIM_CHANNEL_1
TIM14.Period=4000
TIM14.Prescaler=0
TIM15.Channel-PWM\ Generation1\ CH1=TIM_CHANNEL_1
TIM15.Channel-PWM\ Generation2\ CH2=TIM_CHANNEL_2
TIM15.Period=210
TIM15.Prescaler=25
TIM15.Pulse-PWM\ Generation1\ CH1=42
TIM16.AutoReloadPreload=TIM_AUTORELOAD_PRELOAD_DISABLE
TIM16.Channel=TIM_CHANNEL_1
TIM16.Period=600
TIM16.Prescaler=100
TIM16.Pulse=300
TIM2.AutoReloadPreload=TIM_AUTORELOAD_PRELOAD_DISABLE
TIM2.EncoderMode=TIM_ENCODERMODE_TI12
TIM2.Period=65535
TIM2.Prescaler=0
TIM3.AutoReloadPreload=TIM_AUTORELOAD_PRELOAD_DISABLE
TIM3.EncoderMode=TIM_ENCODERMODE_TI12
TIM3.Period=65535
TIM4.EncoderMode=TIM_ENCODERMODE_TI12
TIM4.Period=65535
TIM5.Channel-Output\ Compare1\ No\ Output=TIM_CHANNEL_1
TIM5.Period=2000
TIM5.Prescaler=200
USART3.BaudRate=115200
USART3.VirtualMode-Asynchronous=VM_ASYNC
VP_TIM12_VS_OPM.Mode=OPM_bit
VP_TIM14_VS_ClockSourceINT.Mode=Enable_Timer
VP_TIM16_VS_ClockSourceINT.Mode=Enable_Timer
VP_TIM5_VS_no_output1.Mode=Output Compare1 No Output
board=custom

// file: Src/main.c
/* USER CODE BEGIN Header */
/**
  ******************************************************************************
  * @file           : main.c
  * @brief          : Main program body
  ******************************************************************************
  ** This notice applies to any and all portions of this file
  * that are not between comment pairs USER CODE BEGIN and
  * USER CODE END. Other portions of this file, whether
  * inserted by the user or by software development tools
  * are owned by their respective copyright owners.
  *
  * COPYRIGHT(c) 2018 STMicroelectronics
  *
  * Redistribution and use in source and binary forms, with or without modification,
  * are permitted provided that the following conditions are met:
  *   1. Redistributions of source code must retain the above copyright notice,
  *      this list of conditions and the following disclaimer.
  *   2. Redistributions in binary form must reproduce the above copyright notice,
  *      this list of conditions and the following disclaimer in the documentation
  *      and/or other materials provided with the distribution.
  *   3. Neither the name of STMicroelectronics nor the names of its contributors
  *      may be used to endorse or promote products derived from this software
  *      without specific prior written permission.
  *
  * THIS SOFTWARE IS PROVIDED BY THE COPYRIGHT HOLDERS AND CONTRIBUTORS "AS IS"
  * AND ANY EXPRESS OR IMPLIED WARRANTIES, INCLUDING, BUT NOT LIMITED TO, THE
  * IMPLIED WARRANTIES OF MERCHANTABILITY AND FITNESS FOR A PARTICULAR PURPOSE ARE
  * DISCLAIMED. IN NO EVENT SHALL THE COPYRIGHT HOLDER OR CONTRIBUTORS BE LIABLE
  * FOR ANY DIRECT, INDIRECT, INCIDENTAL, SPECIAL, EXEMPLARY, OR CONSEQUENTIAL
  * DAMAGES (INCLUDING, BUT NOT LIMITED TO, PROCUREMENT OF SUBSTITUTE GOODS OR
  * SERVICES; LOSS OF USE, DATA, OR PROFITS; OR BUSINESS INTERRUPTION) HOWEVER
  * CAUSED AND ON ANY THEORY OF LIABILITY, WHETHER IN CONTRACT, STRICT LIABILITY,
  * OR TORT (INCLUDING NEGLIGENCE OR OTHERWISE) ARISING IN ANY WAY OUT OF THE USE
  * OF THIS SOFTWARE, EVEN IF ADVISED OF THE POSSIBILITY OF SUCH DAMAGE.
  *
  ******************************************************************************
  */
/* USER CODE END Header */

#include "main.h"
#include "adc.h"
#include "dma.h"
#include "hrtim.h"
#include "i2c.h"
#include "spi.h"
#include "tim.h"
#include "usart.h"
#include "gpio.h"

/* USER CODE BEGIN Includes */

#include "string.h"
#include <stdlib.h>
#include <stdio.h>
#include "arm_math.h"
#include "NRF24L01.h"
#include "dma_mine.h"
//#include <cstdio>

/* USER CODE END Includes */

/* USER CODE BEGIN PTD */

void Init_Timers(void);
void Init_PCA9539(void);		//PCA9539初始化
void Buzzer_Ring(void);					//蜂鸣器鸣叫
void Buzzer_Off(void);					//蜂鸣器关闭
void Is_Infrared(void);
uint8_t Shoot_Chip(void);
void Is_BatteryLow_BootCharged(void);
void dribber(void);
void pack(uint8_t *);
//void PWM_SET_VALUE(TIM_HandleTypeDef *htim,uint32_t Channel,uint16_t value);
void unpack(uint8_t *Packet);
void motion_planner(void);

/* USER CODE END PTD */

/* USER CODE BEGIN PV */

//Robot参数
uint8_t tx_freq, tx_mode, rx_freq, rx_mode;								//频点
uint8_t robot_num;
uint8_t robot_set = 0x08;
uint8_t Robot_Is_Infrared; 				//红外触发
uint8_t Robot_Is_Boot_charged; 		//电容充电到60V
uint8_t Robot_drib;
uint8_t Robot_Chip_Or_Shoot;						//chip:1  shoot:0
uint8_t Robot_Is_Shoot;
uint8_t Robot_Is_Chip;
uint8_t shoot_chip_flag = 0;
uint8_t Robot_Boot_Power = 0;
uint8_t Comm_Down_Flag = 0;
////uint8_t Robot_Is_Report;
uint8_t Robot_Chipped = 0, Robot_Shooted = 0;
uint8_t Robot_Status = 0, Last_Robot_Status = 0;
int8_t Left_Report_Package = 0;
uint16_t drib_power, drib_power_set[4] = {0, 3000, 3000, 3000};
//uint8_t selftest_vel_mode = 0x02, selftest_drib_mode = 0x03, selftest_chip_mode = 0x04, selftest_shoot_mode = 0x05, selftest_discharge_mode = 0x06;
//ALIGN_32BYTES(__attribute__((section (".RAM_D2"))) )
uint16_t ADC_value[32];   			//存放ADC采集数据

int16_t Self_Test_Discharge_Flag = 1000;

//电池电压与电容电压累计值
uint32_t AD_Battery = 0,AD_Battery_Last = 217586, AD_Boot_Cap = 0, AD_Boot_Cap_Last, Total_Missed_Package_Num = 0, Period_2ms_Since_Last_Zero_Motion_Planner = 0;
uint8_t AD_Battery_i = 0;

//uint8_t TX_frequency = 0x18;			//NRF24L01发射频率   6号频点时为0x18， 8号频点时为0x5a，
//uint8_t RX_frequency = 0x5a;			//NRF24L01接收频率

int16_t Vx_package = 0, Vy_package = 0, Vr_package = 0;				//下发机器人速度
int16_t Vx_package_last = 0, Vy_package_last = 0, Vr_package_last = 0;				//上一帧下发机器人速度
uint8_t acc_set = 10;			//加速度限制 16ms内合成加速度最大值，单位cm/s
uint16_t acc_r_set = 60;  //
uint8_t RX_Packet[25];				//收包
uint8_t TX_Packet[25] = {0xA5, 0xA5, 0xA5, 0xA5, 0xA5, 0xA5, 0xA5, 0xA5, 0xA5, 0xA5, 0xA5, 0xA5, 0xA5, 0xA5, 0xA5, 0xA5, 0xA5, 0xA5, 0xA5, 0xA5, 0xA5, 0xA5, 0xA5, 0xA5, 0xA5};						//回包

uint16_t Received_packet = 0;
uint16_t transmitted_packet = 0;
uint8_t received_packet_flag = 0;
uint8_t	packet_flag = 0;
uint8_t	to_transmit_packet = 0;
uint16_t miss_packet = 0;			//多久未收包或丢失了多少包
uint8_t	stop_flag = 0;
uint16_t heart_toggle_flag = 0;
uint8_t ADC_circle_i = 0;

//轮子角度
double sin_angle[4] = {0.8480480961564261, -0.8480480961564261, -0.7071067811865476, 0.7071067811865476};					//double sin_angle[4] = {sin(58), -sin(58), -sin(45), sin(45)};
double cos_angle[4] = {0.5299192642332049, 0.5299192642332049, -0.7071067811865476, -0.7071067811865476};					//double cos_angle[4] = {cos(58), cos(58), -cos(45), -cos(45)};

//调试输出
uint8_t temp[200];
uint8_t temp_count = 0;

//计时器计数
uint32_t Time_count = 0;
uint32_t Time_count_last = 0;
uint32_t Interval_count = 0;
uint64_t timer_time = 0;
uint16_t Time_PID_flag = 0;
uint32_t vel_do_flag = 0;

uint16_t chipshoot_timerdelay_flag = 0;

uint16_t selftest_timer_flag = 0;

//时间间隔，单位：ms
double Interval = 0;

//编码器计数
int Encoder_count_Motor1 = 0;
int Encoder_count_Motor2 = 0;
int Encoder_count_Motor3 = 0;
int Encoder_count_Motor4 = 0;

//控制速度与实际速度
int Vel_Motor1_aim = 0, Vel_Motor1 = 0, Vel_Now_Motor1 = 0, Vel_last_Motor1[8], Vel_last_sum_Motor1;																//转速 单位：rpm
int Vel_Motor2_aim = 0, Vel_Motor2 = 0, Vel_Now_Motor2 = 0, Vel_last_Motor2[8], Vel_last_sum_Motor2;																//转速 单位：rpm
int Vel_Motor3_aim = 0, Vel_Motor3 = 0, Vel_Now_Motor3 = 0, Vel_last_Motor3[8], Vel_last_sum_Motor3;																//转速 单位：rpm
int Vel_Motor4_aim = 0, Vel_Motor4 = 0, Vel_Now_Motor4 = 0, Vel_last_Motor4[8], Vel_last_sum_Motor4;																//转速 单位：rpm
//uint8_t vel_filter_flag = 0, vel_filter_temp;

//占空比
double PWM_Pulse_Motor1, PWM_Pulse_Motor2, PWM_Pulse_Motor3, PWM_Pulse_Motor4, PWM_Pulse_Motord;

//实际PWM 占空value
int PWM_Pulse_Motor1_value, PWM_Pulse_Motor2_value, PWM_Pulse_Motor3_value, PWM_Pulse_Motor4_value;

////速度转换系数
//double Vel_k2 = 3.18 *  4 * 360 / 2 / 3.1415926 / 2.8 / 1000 * 2;		//  cm/s  ----->>>>>>>   count/2ms

#ifdef ENCODER_1000
const double Vel_k2 = 1.446036;
#endif

#ifdef ENCODER_360
const double Vel_k2 = 0.520573;
#endif

#if defined(ENCODER_1000) && defined(ROBOT_50W)
const uint32_t Motor_KP = 40, Motor_KI = 11;
const int PID_I_Limit = 720; //7995 / Motor_KI;
#endif

#if defined(ENCODER_360) && defined(ROBOT_50W)
const uint32_t Motor_KP = 110, Motor_KI = 30;
const int PID_I_Limit = 266; //7995 / Motor_KI;
#endif

#if defined(ENCODER_1000) && defined(ROBOT_70W)
const uint32_t Motor_KP = 40, Motor_KI = 11;         //Under Testing
const int PID_I_Limit = 720; //7995 / Motor_KI;
#endif

#if defined(ENCODER_360) && defined(ROBOT_70W)
const uint32_t Motor_KP = 110, Motor_KI = 30;         //Under Testing
const int PID_I_Limit = 266; //7995 / Motor_KI;
#endif

//PID中I积分项
int Motor_EK_Motor1 = 0, Motor_EK_Motor2 = 0, Motor_EK_Motor3 = 0,Motor_EK_Motor4 = 0;
int Motor_KS_Motor1 = 0, Motor_KS_Motor2 = 0, Motor_KS_Motor3 = 0,Motor_KS_Motor4 = 0;

//USART调试
uint16_t USART_flag = 0, USART_flag2 = 0;
/* USER CODE END PV */

void SystemClock_Config(void);

int main(void)
{

  /* Enable I-Cache---------------------------------------------------------*/
  SCB_EnableICache();

  /* MCU Configuration--------------------------------------------------------*/

  /* Reset of all peripherals, Initializes the Flash interface and the Systick. */
  HAL_Init();

  /* Configure the system clock */
  SystemClock_Config();

  /* Initialize all configured peripherals */
  MX_GPIO_Init();
  MX_DMA_Init();
  MX_USART3_UART_Init();
  MX_HRTIM_Init();
  MX_SPI1_Init();
  MX_I2C3_Init();
  MX_TIM2_Init();
  MX_SPI2_Init();
  MX_TIM14_Init();
  MX_TIM1_Init();
  MX_TIM3_Init();
  MX_TIM4_Init();
  MX_ADC1_Init();
  MX_TIM15_Init();
  MX_TIM16_Init();
  MX_TIM12_Init();
  MX_I2C2_Init();
  MX_I2C4_Init();
  MX_TIM5_Init();
  /* USER CODE BEGIN 2 */

	Init_Timers();						//电机及其他Timer和PWM初始化
	Init_PCA9539();   				//PCA9539初始化

	NRF24L01_RX_Init();				//NRF24L01接收初始化
	NRF24L01_TX_Init();				//NRF24L01发送初始化
	RX_Mode();								//NRF24L01设置为接收模式
	TX_Mode();								//NRF24L01设置为发送模式
	HAL_TIM_Base_Start_IT(&htim5);
  /* USER CODE END 2 */

  /* Infinite loop */
  /* USER CODE BEGIN WHILE */
	if((robot_set == 1) && (tx_mode == 0)){					// Self Test Mode

		Buzzer_Ring();
		HAL_Delay(100);
		Buzzer_Off();
		HAL_Delay(200);
		Buzzer_Ring();
		HAL_Delay(100);
		Buzzer_Off();
		HAL_Delay(300);
		Buzzer_Ring();
		HAL_Delay(100);
		Buzzer_Off();

		while(1){
			Init_PCA9539();   											//PCA9539 Get Set Num Tx Rx Number
			Is_Infrared();
			HAL_Delay(1);
			switch(robot_set){
				case 2 :
						drib_power = 0;
						Robot_Boot_Power = 0;
						if(tx_mode <= 8)
							Vx_package = 10 * tx_mode;
						else
							Vx_package = 10 * (tx_mode - 17);
						motion_planner();
				break;

				case 3 :
					Robot_Boot_Power = 0;
					Vx_package = 0;
					motion_planner();
					if(Robot_Is_Infrared == 0){
						drib_power = drib_power_set[1];
					}
					else{
						drib_power = drib_power_set[3];
					}
				break;

				case 4 :
					drib_power = 0;
					Vx_package = 0;
					motion_planner();
					Is_BatteryLow_BootCharged();			//电池电压是否低于15.2V，电容是否充电到60V
					Robot_Boot_Power = 10 * tx_mode;
					if (Robot_Boot_Power > 127) {
						Robot_Boot_Power = 127;
					}
					if (Robot_Is_Boot_charged && (Robot_Boot_Power != 0) && (Robot_Is_Infrared == 1) && (Self_Test_Discharge_Flag == 0)){
						htim12.Instance = TIM12;
						htim12.Init.Period = Robot_Boot_Power * 250 + 10;
						htim12.Instance->CCR1 = 10;
						htim12.Instance->CCR2 = Robot_Boot_Power * 250 + 10;
						HAL_TIM_PWM_Init(&htim12);
						HAL_TIM_PWM_Start(&htim12, TIM_CHANNEL_1);
						Self_Test_Discharge_Flag = 1000;
					}
					else{
						Self_Test_Discharge_Flag --;
						if (Self_Test_Discharge_Flag<0) Self_Test_Discharge_Flag = 0;
					}
				break;

				case 5 :
					drib_power = 0;
					Vx_package = 0;
					motion_planner();
					Is_BatteryLow_BootCharged();			//电池电压是否低于15.2V，电容是否充电到60V
					Robot_Boot_Power = 10 * tx_mode;
					if (Robot_Boot_Power > 127) {
						Robot_Boot_Power = 127;
					}
					if (Robot_Is_Boot_charged && (Robot_Boot_Power != 0) && (Robot_Is_Infrared == 1) && (Self_Test_Discharge_Flag == 0)){
						htim12.Instance = TIM12;
						htim12.Init.Period = Robot_Boot_Power * 250 + 10;
						htim12.Instance->CCR1 = Robot_Boot_Power * 250 + 10;
						htim12.Instance->CCR2 = 10;
						HAL_TIM_PWM_Init(&htim12);
						HAL_TIM_PWM_Start(&htim12, TIM_CHANNEL_2);
						Self_Test_Discharge_Flag = 1000;
					}
					else{
						Self_Test_Discharge_Flag --;
						if (Self_Test_Discharge_Flag<0) Self_Test_Discharge_Flag = 0;
					}
				break;

				case 6 :
					drib_power = 0;
					Vx_package = 0;
					motion_planner();
					Is_BatteryLow_BootCharged();
					Robot_Boot_Power = 50;
					if (Robot_Is_Boot_charged && (Robot_Boot_Power != 0) && (Self_Test_Discharge_Flag == 0)){
						htim12.Instance = TIM12;
						htim12.Init.Period = Robot_Boot_Power * 250 + 10;
						htim12.Instance->CCR1 = 10;
						htim12.Instance->CCR2 = Robot_Boot_Power * 250 + 10;
						HAL_TIM_PWM_Init(&htim12);
						HAL_TIM_PWM_Start(&htim12, TIM_CHANNEL_1);
						Self_Test_Discharge_Flag = 1000;
					}
					else{
						Self_Test_Discharge_Flag --;
						if (Self_Test_Discharge_Flag<0) Self_Test_Discharge_Flag = 0;
					}
				break;
				default :
					drib_power = 0;
					Vx_package = 0;
					Robot_Boot_Power = 0;
					motion_planner();
				break;
			}
		}
	}

  while(1)
  {

//		//调试输出
//		sprintf(temp, "%d", AD_Battery_Last);
//		HAL_UART_Transmit(&huart3, &robot_num, 1, 0xffff);

//////		//接收2401 check
//////		if(NRF24L01_TX_Check() == 0){
//////			HAL_GPIO_TogglePin(TX_COM_GPIO_Port, TX_COM_Pin);
//////			HAL_Delay(100);
//////		}
//////		if(NRF24L01_RX_Check() == 0){
//////			HAL_GPIO_TogglePin(RX_COM_GPIO_Port, RX_COM_Pin);
//////			HAL_Delay(100);
//////		}

//////		NRF2401DMA调试
//////		NRF24L01_RX_DMA_Check();
//////		HAL_Delay(100);

		if(Received_packet > 30){
			HAL_GPIO_TogglePin(RX_COM_GPIO_Port, RX_COM_Pin);
			Received_packet = 0;
		};
		if(transmitted_packet > 30){
			HAL_GPIO_TogglePin(TX_COM_GPIO_Port, TX_COM_Pin);
			transmitted_packet = 0;
		}

		Is_Infrared();				//是否触发红外
		dribber();
		Is_BatteryLow_BootCharged();			//电池电压是否低于15.2V，电容是否充电到60V
////		平挑射放到2ms中断里面
////		Shoot_Chip();					//平挑射
  }
    /* USER CODE END WHILE */

}

void SystemClock_Config(void)
{
  RCC_OscInitTypeDef RCC_OscInitStruct = {0};
  RCC_ClkInitTypeDef RCC_ClkInitStruct = {0};
  RCC_PeriphCLKInitTypeDef PeriphClkInitStruct = {0};

  /** Supply configuration update enable
  */
  HAL_PWREx_ConfigSupply(PWR_LDO_SUPPLY);
  /** Configure the main internal regulator output voltage
  */
  __HAL_PWR_VOLTAGESCALING_CONFIG(PWR_REGULATOR_VOLTAGE_SCALE1);

  while(!__HAL_PWR_GET_FLAG(PWR_FLAG_VOSRDY)) {}
  /** Macro to configure the PLL clock source
  */
  __HAL_RCC_PLL_PLLSOURCE_CONFIG(RCC_PLLSOURCE_HSE);
  /** Initializes the CPU, AHB and APB busses clocks
  */
  RCC_OscInitStruct.OscillatorType = RCC_OSCILLATORTYPE_HSI|RCC_OSCILLATORTYPE_HSE;
  RCC_OscInitStruct.HSEState = RCC_HSE_ON;
  RCC_OscInitStruct.HSIState = RCC_HSI_DIV1;
  RCC_OscInitStruct.HSICalibrationValue = RCC_HSICALIBRATION_DEFAULT;
  RCC_OscInitStruct.PLL.PLLState = RCC_PLL_ON;
  RCC_OscInitStruct.PLL.PLLSource = RCC_PLLSOURCE_HSE;
  RCC_OscInitStruct.PLL.PLLM = 1;
  RCC_OscInitStruct.PLL.PLLN = 100;
  RCC_OscInitStruct.PLL.PLLP = 2;
  RCC_OscInitStruct.PLL.PLLQ = 2;
  RCC_OscInitStruct.PLL.PLLR = 4;
  RCC_OscInitStruct.PLL.PLLRGE = RCC_PLL1VCIRANGE_3;
  RCC_OscInitStruct.PLL.PLLVCOSEL = RCC_PLL1VCOWIDE;
  RCC_OscInitStruct.PLL.PLLFRACN = 0;
  if (HAL_RCC_OscConfig(&RCC_OscInitStruct) != HAL_OK)
  {
    Error_Handler();
  }
  /** Initializes the CPU, AHB and APB busses clocks
  */
  RCC_ClkInitStruct.ClockType = RCC_CLOCKTYPE_HCLK|RCC_CLOCKTYPE_SYSCLK
                              |RCC_CLOCKTYPE_PCLK1|RCC_CLOCKTYPE_PCLK2
                              |RCC_CLOCKTYPE_D3PCLK1|RCC_CLOCKTYPE_D1PCLK1;
  RCC_ClkInitStruct.SYSCLKSource = RCC_SYSCLKSOURCE_PLLCLK;
  RCC_ClkInitStruct.SYSCLKDivider = RCC_SYSCLK_DIV1;
  RCC_ClkInitStruct.AHBCLKDivider = RCC_HCLK_DIV2;
  RCC_ClkInitStruct.APB3CLKDivider = RCC_APB3_DIV2;
  RCC_ClkInitStruct.APB1CLKDivider = RCC_APB1_DIV2;
  RCC_ClkInitStruct.APB2CLKDivider = RCC_APB2_DIV2;
  RCC_ClkInitStruct.APB4CLKDivider = RCC_APB4_DIV2;

  if (HAL_RCC_ClockConfig(&RCC_ClkInitStruct, FLASH_LATENCY_2) != HAL_OK)
  {
    Error_Handler();
  }
  PeriphClkInitStruct.PeriphClockSelection = RCC_PERIPHCLK_HRTIM1|RCC_PERIPHCLK_USART3
                              |RCC_PERIPHCLK_SPI1|RCC_PERIPHCLK_SPI2
                              |RCC_PERIPHCLK_I2C2|RCC_PERIPHCLK_I2C3
                              |RCC_PERIPHCLK_ADC|RCC_PERIPHCLK_I2C4
                              |RCC_PERIPHCLK_CKPER;
  PeriphClkInitStruct.PLL2.PLL2M = 1;
  PeriphClkInitStruct.PLL2.PLL2N = 32;
  PeriphClkInitStruct.PLL2.PLL2P = 4;
  PeriphClkInitStruct.PLL2.PLL2Q = 2;
  PeriphClkInitStruct.PLL2.PLL2R = 2;
  PeriphClkInitStruct.PLL2.PLL2RGE = RCC_PLL2VCIRANGE_3;
  PeriphClkInitStruct.PLL2.PLL2VCOSEL = RCC_PLL2VCOMEDIUM;
  PeriphClkInitStruct.PLL2.PLL2FRACN = 0;
  PeriphClkInitStruct.CkperClockSelection = RCC_CLKPSOURCE_HSI;
  PeriphClkInitStruct.Spi123ClockSelection = RCC_SPI123CLKSOURCE_PLL2;
  PeriphClkInitStruct.Usart234578ClockSelection = RCC_USART234578CLKSOURCE_D2PCLK1;
  PeriphClkInitStruct.I2c123ClockSelection = RCC_I2C123CLKSOURCE_D2PCLK1;
  PeriphClkInitStruct.I2c4ClockSelection = RCC_I2C4CLKSOURCE_D3PCLK1;
  PeriphClkInitStruct.AdcClockSelection = RCC_ADCCLKSOURCE_CLKP;
  PeriphClkInitStruct.Hrtim1ClockSelection = RCC_HRTIM1CLK_CPUCLK;
  if (HAL_RCCEx_PeriphCLKConfig(&PeriphClkInitStruct) != HAL_OK)
  {
    Error_Handler();
  }
}

/* USER CODE BEGIN 4 */

//时钟中断
void HAL_TIM_PeriodElapsedCallback(TIM_HandleTypeDef *htim)
{
	if (htim->Instance == htim5.Instance)
	{
			//码盘读数与计时器读数  差分码盘
			#ifdef ENCODER_1000
			Encoder_count_Motor1 =  (int16_t)(__HAL_TIM_GET_COUNTER(&htim1));
			__HAL_TIM_SET_COUNTER(&htim1,0);
			Encoder_count_Motor2 =  (int16_t)(__HAL_TIM_GET_COUNTER(&htim2));
			__HAL_TIM_SET_COUNTER(&htim2,0);
			Encoder_count_Motor3 =  (int16_t)(__HAL_TIM_GET_COUNTER(&htim3)) ;
			__HAL_TIM_SET_COUNTER(&htim3,0);
			Encoder_count_Motor4 =  (int16_t)(__HAL_TIM_GET_COUNTER(&htim4));
			__HAL_TIM_SET_COUNTER(&htim4,0);
			#endif

			#ifdef ENCODER_360
			Encoder_count_Motor1 =  -(int16_t)(__HAL_TIM_GET_COUNTER(&htim1));
			__HAL_TIM_SET_COUNTER(&htim1,0);
			Encoder_count_Motor2 =  -(int16_t)(__HAL_TIM_GET_COUNTER(&htim2));
			__HAL_TIM_SET_COUNTER(&htim2,0);
			Encoder_count_Motor3 =  -(int16_t)(__HAL_TIM_GET_COUNTER(&htim3)) ;
			__HAL_TIM_SET_COUNTER(&htim3,0);
			Encoder_count_Motor4 =  -(int16_t)(__HAL_TIM_GET_COUNTER(&htim4));
			__HAL_TIM_SET_COUNTER(&htim4,0);
			#endif
			//计算轮子转速
			Vel_Now_Motor1 = Encoder_count_Motor1;
			Vel_Now_Motor2 = Encoder_count_Motor2;
			Vel_Now_Motor3 = Encoder_count_Motor3;
			Vel_Now_Motor4 = Encoder_count_Motor4;

			//PID EK项
			Motor_EK_Motor1 = Vel_Motor1 - Vel_Now_Motor1;
			Motor_EK_Motor2 = Vel_Motor2 - Vel_Now_Motor2;
			Motor_EK_Motor3 = Vel_Motor3 - Vel_Now_Motor3;
			Motor_EK_Motor4 = Vel_Motor4 - Vel_Now_Motor4;

			//PID I积分项
			Motor_KS_Motor1 += Motor_EK_Motor1;
			Motor_KS_Motor2 += Motor_EK_Motor2;
			Motor_KS_Motor3 += Motor_EK_Motor3;
			Motor_KS_Motor4 += Motor_EK_Motor4;

			if ((Motor_KS_Motor1)> PID_I_Limit) Motor_KS_Motor1= PID_I_Limit;
			if ((Motor_KS_Motor1)<-PID_I_Limit) Motor_KS_Motor1=-PID_I_Limit;

			if ((Motor_KS_Motor2)> PID_I_Limit) Motor_KS_Motor2= PID_I_Limit;
			if ((Motor_KS_Motor2)<-PID_I_Limit) Motor_KS_Motor2=-PID_I_Limit;

			if ((Motor_KS_Motor3)> PID_I_Limit) Motor_KS_Motor3= PID_I_Limit;
			if ((Motor_KS_Motor3)<-PID_I_Limit) Motor_KS_Motor3=-PID_I_Limit;

			if ((Motor_KS_Motor4)> PID_I_Limit) Motor_KS_Motor4= PID_I_Limit;
			if ((Motor_KS_Motor4)<-PID_I_Limit) Motor_KS_Motor4=-PID_I_Limit;

			//PID
			PWM_Pulse_Motor1_value = Motor_KP * Motor_EK_Motor1 + Motor_KI * Motor_KS_Motor1;
			PWM_Pulse_Motor2_value = Motor_KP * Motor_EK_Motor2 + Motor_KI * Motor_KS_Motor2;
			PWM_Pulse_Motor3_value = Motor_KP * Motor_EK_Motor3 + Motor_KI * Motor_KS_Motor3;
			PWM_Pulse_Motor4_value = Motor_KP * Motor_EK_Motor4 + Motor_KI * Motor_KS_Motor4;

			//最大占空比限制
			PWM_Pulse_Motor1_value = (PWM_Pulse_Motor1_value >= 7995) ? 7995 : PWM_Pulse_Motor1_value;
			PWM_Pulse_Motor1_value = (PWM_Pulse_Motor1_value <= -7995) ? -7995 : PWM_Pulse_Motor1_value;
			PWM_Pulse_Motor2_value = (PWM_Pulse_Motor2_value >= 7995) ? 7995 : PWM_Pulse_Motor2_value;
			PWM_Pulse_Motor2_value = (PWM_Pulse_Motor2_value <= -7995) ? -7995 : PWM_Pulse_Motor2_value;
			PWM_Pulse_Motor3_value = (PWM_Pulse_Motor3_value >= 7995) ? 7995 : PWM_Pulse_Motor3_value;
			PWM_Pulse_Motor3_value = (PWM_Pulse_Motor3_value <= -7995) ? -7995 : PWM_Pulse_Motor3_value;
			PWM_Pulse_Motor4_value = (PWM_Pulse_Motor4_value >= 7995) ? 7995 : PWM_Pulse_Motor4_value;
			PWM_Pulse_Motor4_value = (PWM_Pulse_Motor4_value <= -7995) ? -7995 : PWM_Pulse_Motor4_value;

			//控制
			//HRTIM1->sTimerxRegs[HRTIM_TIMERINDEX_TIMER_A].CMP1xR = 4000 + PWM_Pulse_Motor1_value;
			if (PWM_Pulse_Motor1_value<0) {HAL_GPIO_WritePin(MOTOR1_DIR_GPIO_Port, MOTOR1_DIR_Pin, GPIO_PIN_RESET);}
				else {HAL_GPIO_WritePin(MOTOR1_DIR_GPIO_Port, MOTOR1_DIR_Pin, GPIO_PIN_SET);}
			if (abs(PWM_Pulse_Motor1_value)<=3) PWM_Pulse_Motor1_value = 3;
			HRTIM1->sTimerxRegs[HRTIM_TIMERINDEX_TIMER_A].CMP1xR = abs(PWM_Pulse_Motor1_value);

			if (PWM_Pulse_Motor2_value<0) {HAL_GPIO_WritePin(MOTOR2_DIR_GPIO_Port, MOTOR2_DIR_Pin, GPIO_PIN_RESET);}
			  else {HAL_GPIO_WritePin(MOTOR2_DIR_GPIO_Port, MOTOR2_DIR_Pin, GPIO_PIN_SET);}
			if (abs(PWM_Pulse_Motor2_value)<=3) PWM_Pulse_Motor2_value = 3;
			HRTIM1->sTimerxRegs[HRTIM_TIMERINDEX_TIMER_C].CMP1xR = abs(PWM_Pulse_Motor2_value);

			if (PWM_Pulse_Motor3_value<0) {HAL_GPIO_WritePin(MOTOR3_DIR_GPIO_Port, MOTOR3_DIR_Pin, GPIO_PIN_RESET);}
				else {HAL_GPIO_WritePin(MOTOR3_DIR_GPIO_Port, MOTOR3_DIR_Pin, GPIO_PIN_SET);}
			if (abs(PWM_Pulse_Motor3_value)<=3) PWM_Pulse_Motor3_value = 3;
			HRTIM1->sTimerxRegs[HRTIM_TIMERINDEX_TIMER_D].CMP1xR = abs(PWM_Pulse_Motor3_value);

			if (PWM_Pulse_Motor4_value<0) {HAL_GPIO_WritePin(MOTOR4_DIR_GPIO_Port, MOTOR4_DIR_Pin, GPIO_PIN_RESET);}
				else {HAL_GPIO_WritePin(MOTOR4_DIR_GPIO_Port, MOTOR4_DIR_Pin, GPIO_PIN_SET);}
			if (abs(PWM_Pulse_Motor4_value)<=3) PWM_Pulse_Motor4_value = 3;
			HRTIM1->sTimerxRegs[HRTIM_TIMERINDEX_TIMER_B].CMP1xR = abs(PWM_Pulse_Motor4_value);

			heart_toggle_flag ++;
			if(heart_toggle_flag == 500){
				HAL_GPIO_TogglePin(HEART_GPIO_Port, HEART_Pin);
				heart_toggle_flag = 0;
			}

			htim14.Instance->CCR1 = drib_power;				//吸球

			if(NRF24L01_RxPacket(RX_Packet) == 0){
				unpack(RX_Packet);
				if(received_packet_flag == 1){
					motion_planner();
					Received_packet++;
					Total_Missed_Package_Num = 0;
					Comm_Down_Flag = 0;
					if ((Robot_Status != Last_Robot_Status) || ((Robot_Status & 0x40) == 0x40)) {
						Left_Report_Package = 5;
						Last_Robot_Status = Robot_Status;
					}
					else{
						if(Left_Report_Package >= 0)
							Left_Report_Package --;
						Last_Robot_Status = Robot_Status;
					}
					if(Left_Report_Package > 0){
						pack(TX_Packet);
						NRF24L01_TxPacket(TX_Packet);
						transmitted_packet++;
					}
					else{
						Robot_Status = 0;
						Last_Robot_Status = 0;
					}
				}
			}
				else {
					received_packet_flag = 0;
				}
			if (Comm_Down_Flag == 1){
				Period_2ms_Since_Last_Zero_Motion_Planner ++;
				if (Period_2ms_Since_Last_Zero_Motion_Planner>=8){
					Vy_package = 0;
					Vx_package = 0;
					Vr_package = 0;
//					Robot_drib = 0;
					motion_planner();
					Period_2ms_Since_Last_Zero_Motion_Planner = 0;
				}
			}
			else{
				if(received_packet_flag == 0){
					Total_Missed_Package_Num ++;
					if (Total_Missed_Package_Num >= 500){ // 500ms Missing Package -> Every 16ms Do Motion Planner
						Comm_Down_Flag = 1;
						Vy_package = 0;
						Vx_package = 0;
						Vr_package = 0;
//						Robot_drib = 0;
						Period_2ms_Since_Last_Zero_Motion_Planner = 0;
						motion_planner();
					}
				}
			}

			if(chipshoot_timerdelay_flag < 1000)
				chipshoot_timerdelay_flag++;

			Shoot_Chip();					//平挑射
//			if(selftest_timer_flag <= 8)
//				selftest_timer_flag++;
	}
}

//蜂鸣器鸣叫
void Buzzer_Ring(){							//蜂鸣器PWM通道打开，频率2K/0.6，占空比0.5
	//HAL_TIM_PWM_Start(&htim16, TIM_CHANNEL_1);
	htim16.Instance->CCR1=300;
};

//蜂鸣器关闭
void Buzzer_Off(){							//蜂鸣器PWM通道打开，频率2K/0.6，占空比0
	htim16.Instance->CCR1=0;
};

//PCA9539初始化函数
void Init_PCA9539(){
//	uint8_t i;
//	uint8_t PCA9539_REG67_test[2] = {0xa5, 0xa5};
//	uint8_t PCA9539_REG67[2] = {0xff, 0xff};
	uint8_t Pca9539_Read[2];
	uint8_t Pca9539_convert[16] = {15, 7, 11, 3, 13, 5, 9, 1, 14, 6, 10, 2, 12, 4, 8, 0};
	HAL_I2C_Mem_Read(&hi2c3, 0xe8 + (0x03<<1), 0, I2C_MEMADD_SIZE_8BIT, Pca9539_Read, 2, 0x10);
	tx_mode = Pca9539_convert[(Pca9539_Read[0] & 0x0f)];
	rx_mode = Pca9539_convert[(Pca9539_Read[0] >> 4)];
	if(tx_mode < 0x08){
		tx_freq = 4 * tx_mode;
	}
	else{
		tx_freq = 58 + 4 * tx_mode;
	}
	if (tx_mode == 1) tx_freq = 88;
	if (tx_mode == 2) tx_freq = 100;
	if(rx_mode < 0x08){
		rx_freq = 4 * rx_mode;
	}
	else{
		rx_freq = 58 + 4 * rx_mode;
	}
	if (rx_mode == 1) rx_freq = 88;
	if (rx_mode == 2) rx_freq = 100;
	robot_num = Pca9539_convert[(Pca9539_Read[1] & 0x0f)] - 1;
	robot_set = Pca9539_convert[(Pca9539_Read[1] >> 4)];
}

//红外是否触发
void Is_Infrared(){
	if(HAL_GPIO_ReadPin(INFRAIN_GPIO_Port, INFRAIN_Pin) == 0){
		HAL_GPIO_WritePin(INFRA_LED_GPIO_Port, INFRA_LED_Pin, GPIO_PIN_SET);
		Robot_Is_Infrared = 0;
		Robot_Status = Robot_Status & 0x30;
	}
	else{
		HAL_GPIO_WritePin(INFRA_LED_GPIO_Port, INFRA_LED_Pin, GPIO_PIN_RESET);
		Robot_Is_Infrared = 1;
		Robot_Status = Robot_Status | (1 << 6);
	}
}

//ADC采集
//电池电压是否低于15.2V，电容是否充电到60V
//Battery_Voltage  分压比22/3.3
//Boot_Cap_Voltage 分压比200/3.9
void Is_BatteryLow_BootCharged(){
	//SCB_InvalidateDCache_by_Addr ((uint32_t *)ADC_value, 2);
	AD_Battery = AD_Battery + ADC_value[0];
	AD_Boot_Cap = ADC_value[1];

	if(AD_Battery_i >= 5){
		AD_Battery_Last = ((AD_Battery << 2) + (AD_Battery << 1) + AD_Battery + AD_Battery_Last) >> 3;
		AD_Battery = 0;
		AD_Battery_i = 0;
	}
	AD_Battery_i ++;

	//电池电压低于15.2V，196864 = 15.2/25.3*3.3/3.3*65535*5
	//电池电压高于3.3V，42740 = 3.3/25.3*3.3/3.3*65535*5   189600
	if(AD_Battery_Last < 189600)
//	if((AD_Battery_Last > 122740)&&(AD_Battery_Last < 189600))
		htim16.Instance->CCR1=300;
	else
		htim16.Instance->CCR1=0;

	//电容升压到60V，11797 = 60/1010*10/3.3*65535
	if(AD_Boot_Cap > 12000){
		Robot_Is_Boot_charged = 1;
		HAL_GPIO_WritePin(BOOT_DONE_GPIO_Port, BOOT_DONE_Pin, GPIO_PIN_RESET);
	}
	else{
		Robot_Is_Boot_charged = 0;
		HAL_GPIO_WritePin(BOOT_DONE_GPIO_Port, BOOT_DONE_Pin, GPIO_PIN_SET);
	}
}

//吸球
void dribber(void){
//	Robot_drib = 3;
	if (Robot_drib == 0){
		drib_power = 0;
		return;
	}
	if (Robot_Is_Infrared == 1){
		drib_power = drib_power_set[Robot_drib];
	}
	else {
		drib_power = drib_power_set[1];
	}
}

//平挑射
uint8_t Shoot_Chip(){
//////	Robot_Chip_Or_Shoot = 1;
//////	Robot_Boot_Power = 50;
//////	if((Robot_Boot_Power > 0) && (chipshoot_timerdelay_flag >= 1000)){

//////
//////	//不用升压test
//////	if((Robot_Boot_Power > 0) && (Robot_Is_Infrared == 1) && (chipshoot_timerdelay_flag >= 1000)){

	//inuse
	if((Robot_Boot_Power > 0) && (Robot_Is_Boot_charged == 1) && (Robot_Is_Infrared == 1) && (chipshoot_timerdelay_flag >= 500)){
		if(Robot_Chip_Or_Shoot == 1){
				Robot_Is_Chip = 1;

//////				htim12.Instance->CCR1 = 32000 - Robot_Boot_Power * 250;
//////				htim12.Instance->CCR2 = 32000;
//////				htim12.Instance = TIM12;

				htim12.Instance = TIM12;
				htim12.Init.Period = Robot_Boot_Power * 250 + 10;
				htim12.Instance->CCR1 = 10;
				htim12.Instance->CCR2 = Robot_Boot_Power * 250 + 10;

				HAL_TIM_PWM_Init(&htim12);
				HAL_TIM_PWM_Start(&htim12, TIM_CHANNEL_1);

				Robot_Status = Robot_Status | (1 << 4);
				Robot_Boot_Power = 0;
				chipshoot_timerdelay_flag  = 0;
				Robot_Chip_Or_Shoot = 2;

				return 0;
		}
		if(Robot_Chip_Or_Shoot == 0){
				Robot_Is_Shoot = 1;

//////				htim12.Instance->CCR2 = 32000 - Robot_Boot_Power * 250;
//////				htim12.Instance->CCR1 = 32000;
//////				htim12.Instance = TIM12;

				htim12.Instance = TIM12;
				htim12.Init.Period = Robot_Boot_Power * 250 + 0 + 10;
				htim12.Instance->CCR2 = 10;
				htim12.Instance->CCR1 = Robot_Boot_Power * 250 + 0 + 10;

				HAL_TIM_PWM_Init(&htim12);
				HAL_TIM_PWM_Start(&htim12, TIM_CHANNEL_2);

				Robot_Chip_Or_Shoot = 2;
				Robot_Status = Robot_Status | (1 << 5);
				Robot_Boot_Power = 0;
				chipshoot_timerdelay_flag  = 0;

				return 0;
		}
	}
	return 0;
}

//电机及其他Timer和PWM初始化
void Init_Timers(){
	//Motor1对应的Timer打开及PWM设置
	HRTIM1->sTimerxRegs[HRTIM_TIMERINDEX_TIMER_A].CMP1xR = 3;
	HAL_HRTIM_WaveformOutputStart(&hhrtim, HRTIM_OUTPUT_TA1);//通道打开
	HAL_HRTIM_WaveformCounterStart(&hhrtim, HRTIM_TIMERID_TIMER_A);//开启定时器
	HAL_GPIO_WritePin(MOTOR1_RESET_GPIO_Port, MOTOR1_RESET_Pin, GPIO_PIN_SET);
	HAL_GPIO_WritePin(MOTOR1_MODE_GPIO_Port, MOTOR1_MODE_Pin, GPIO_PIN_SET);
	HAL_GPIO_WritePin(MOTOR1_DIR_GPIO_Port, MOTOR1_DIR_Pin, GPIO_PIN_SET);

	//Motor2对应的Timer打开及PWM设置
	HRTIM1->sTimerxRegs[HRTIM_TIMERINDEX_TIMER_C].CMP1xR = 3;
	HAL_HRTIM_WaveformOutputStart(&hhrtim, HRTIM_OUTPUT_TC2);//通道打开
	HAL_HRTIM_WaveformCounterStart(&hhrtim, HRTIM_TIMERID_TIMER_C);//开启定时器
	HAL_GPIO_WritePin(MOTOR2_RESET_GPIO_Port, MOTOR2_RESET_Pin, GPIO_PIN_SET);
	HAL_GPIO_WritePin(MOTOR2_MODE_GPIO_Port, MOTOR2_MODE_Pin, GPIO_PIN_SET);
	HAL_GPIO_WritePin(MOTOR2_DIR_GPIO_Port, MOTOR2_DIR_Pin, GPIO_PIN_SET);

	//Motor3对应的Timer打开及PWM设置
	HRTIM1->sTimerxRegs[HRTIM_TIMERINDEX_TIMER_D].CMP1xR = 3;
	HAL_HRTIM_WaveformOutputStart(&hhrtim, HRTIM_OUTPUT_TD2);//通道打开
	HAL_HRTIM_WaveformCounterStart(&hhrtim, HRTIM_TIMERID_TIMER_D);//开启定时器
	HAL_GPIO_WritePin(MOTOR3_RESET_GPIO_Port, MOTOR3_RESET_Pin, GPIO_PIN_SET);
	HAL_GPIO_WritePin(MOTOR3_MODE_GPIO_Port, MOTOR3_MODE_Pin, GPIO_PIN_SET);
	HAL_GPIO_WritePin(MOTOR3_DIR_GPIO_Port, MOTOR3_DIR_Pin, GPIO_PIN_SET);

	//Motor4对应的Timer打开及PWM设置
	HRTIM1->sTimerxRegs[HRTIM_TIMERINDEX_TIMER_B].CMP1xR = 3;
	HAL_HRTIM_WaveformOutputStart(&hhrtim, HRTIM_OUTPUT_TB1);//通道打开
	HAL_HRTIM_WaveformCounterStart(&hhrtim, HRTIM_TIMERID_TIMER_B);//开启定时器
	HAL_GPIO_WritePin(MOTOR4_RESET_GPIO_Port, MOTOR4_RESET_Pin, GPIO_PIN_SET);
	HAL_GPIO_WritePin(MOTOR4_MODE_GPIO_Port, MOTOR4_MODE_Pin, GPIO_PIN_SET);
	HAL_GPIO_WritePin(MOTOR4_DIR_GPIO_Port, MOTOR4_DIR_Pin, GPIO_PIN_SET);

	//MotorD对应的Timer打开及PWM设置
	//PWM_SET_VALUE(,TIM_CHANNEL_1,2000);						//通道打开
	HAL_TIM_PWM_Start(&htim14, TIM_CHANNEL_1);
	htim14.Instance->CCR1 = 0;
	HAL_GPIO_WritePin(MOTORD_RESET_GPIO_Port, MOTORD_RESET_Pin, GPIO_PIN_SET);
	HAL_GPIO_WritePin(MOTORD_MODE_GPIO_Port, MOTORD_MODE_Pin, GPIO_PIN_SET);
	HAL_GPIO_WritePin(MOTORD_DIR_GPIO_Port, MOTORD_DIR_Pin, GPIO_PIN_RESET);

	//4路电机Encoder对应的Timer打开
	HAL_TIM_Encoder_Start(&htim1, TIM_CHANNEL_ALL);
	HAL_TIM_Encoder_Start(&htim2, TIM_CHANNEL_ALL);
	HAL_TIM_Encoder_Start(&htim3, TIM_CHANNEL_ALL);
	HAL_TIM_Encoder_Start(&htim4, TIM_CHANNEL_ALL);

	//4路电机对应的Timer计时打开

	//红外对应的Timer打开
	HAL_TIM_PWM_Start(&htim15, TIM_CHANNEL_1);							//红外PWM通道打开，频率38K，占空比0.2

	//蜂鸣器叫100ms
	HAL_TIM_PWM_Start(&htim16, TIM_CHANNEL_1);
	htim16.Instance->CCR1 = 300;
	//PWM_SET_VALUE(&htim16,TIM_CHANNEL_1,300);
	HAL_Delay(100);
	//PWM_SET_VALUE(&htim16,TIM_CHANNEL_1,0);
	htim16.Instance->CCR1 = 0;

	//启动ADC转换
//	memset(ADC_value, 0, sizeof(ADC_value));
	HAL_ADC_Start_DMA(&hadc1, (uint32_t *)&ADC_value, 32);

//	HAL_TIM_Base_Start(&htim12);
//	Robot_Boot_Power = 0;
//	htim12.Instance->CCR1 = 65535 - Robot_Boot_Power * 50;
//	HAL_TIM_PWM_Start(&htim12, TIM_CHANNEL_1);
}

////////////设置占空比PWM
//////////void PWM_SET_VALUE(TIM_HandleTypeDef *htim,uint32_t Channel,uint16_t value)
//////////{
//////////	TIM_OC_InitTypeDef sConfigOC;
//////////	uint32_t pluse = value;
//////////	sConfigOC.OCMode = TIM_OCMODE_PWM1;
//////////	sConfigOC.Pulse = pluse;
//////////	sConfigOC.OCPolarity = TIM_OCPOLARITY_HIGH;
//////////	sConfigOC.OCFastMode = TIM_OCFAST_DISABLE;
//////////	if(htim == &htim16){
//////////		sConfigOC.OCIdleState = TIM_OCIDLESTATE_RESET;
//////////		sConfigOC.OCNIdleState = TIM_OCNIDLESTATE_RESET;
//////////	}
//////////	HAL_TIM_PWM_ConfigChannel(htim, &sConfigOC, Channel);
//////////	HAL_TIM_PWM_Start(htim, Channel);
//////////}

//解包，到每个轮子的速度
void unpack(uint8_t *Packet){
	if((Packet[0] & 0xf0) == 0x40){
		if((robot_num == (Packet[1] & 0x0f)) && (Packet[0] & 0x08)){
			received_packet_flag = 1;
			Vx_package = (Packet[2] & 0x7f) + ((Packet[17] & 0xc0) << 1);
			Vx_package = (Packet[2] & 0x80) ? ( -Vx_package ) : Vx_package;
			Vy_package = (Packet[3] & 0x7f) + ((Packet[17] & 0x30) << 3);
			Vy_package = (Packet[3] & 0x80) ? ( -Vy_package ) : Vy_package;
			Vr_package = (Packet[4] & 0x7f) + ((Packet[17] & 0x0f) << 7);
			Vr_package = (Packet[4] & 0x80) ? ( -Vr_package ) : Vr_package;
//			Robot_Is_Report = Packet[1] >> 7;
			Robot_drib = (Packet[1] >> 4) & 0x03;
			Robot_Chip_Or_Shoot = ( Packet[1] >> 6 ) & 0x01;
			Robot_Boot_Power = Packet[21] & 0x7f;
		}
		else if((robot_num == (Packet[5] & 0x0f)) && (Packet[0] & 0x04)){
			received_packet_flag = 1;
			Vx_package = (Packet[6] & 0x7f) + ((Packet[18] & 0xc0) << 1);
			Vx_package = (Packet[6] & 0x80) ? ( -Vx_package ) : Vx_package;
			Vy_package = (Packet[7] & 0x7f) + ((Packet[18] & 0x30) << 3);
			Vy_package = (Packet[7] & 0x80) ? ( -Vy_package ) : Vy_package;
			Vr_package = (Packet[8] & 0x7f) + ((Packet[18] & 0x0f) << 7);
			Vr_package = (Packet[8] & 0x80) ? ( -Vr_package ) : Vr_package;
//			Robot_Is_Report = Packet[5] >> 7;
			Robot_drib = (Packet[5] >> 4) & 0x03;
			Robot_Chip_Or_Shoot = ( Packet[5] >> 6 ) & 0x01;
			Robot_Boot_Power = Packet[22] & 0x7f;
		}
		else if((robot_num == (Packet[9] & 0x0f)) && (Packet[0] & 0x02)){
			received_packet_flag = 1;
			Vx_package = (Packet[10] & 0x7f) + ((Packet[19] & 0xc0) << 1);
			Vx_package = (Packet[10] & 0x80) ? ( -Vx_package ) : Vx_package;
			Vy_package = (Packet[11] & 0x7f) + ((Packet[19] & 0x30) << 3);
			Vy_package = (Packet[11] & 0x80) ? ( -Vy_package ) : Vy_package;
			Vr_package = (Packet[12] & 0x7f) + ((Packet[19] & 0x0f) << 7);
			Vr_package = (Packet[12] & 0x80) ? ( -Vr_package ) : Vr_package;
//			Robot_Is_Report = Packet[9] >> 7;
			Robot_drib = (Packet[9] >> 4) & 0x03;
			Robot_Chip_Or_Shoot = ( Packet[9] >> 6 ) & 0x01;
			Robot_Boot_Power = Packet[23] & 0x7f;
		}
		else if((robot_num == (Packet[13] & 0x0f)) && (Packet[0] & 0x01)){
			received_packet_flag = 1;
			Vx_package = (Packet[14] & 0x7f) + ((Packet[20] & 0xc0) << 1);
			Vx_package = (Packet[14] & 0x80) ? ( -Vx_package ) : Vx_package;
			Vy_package = (Packet[15] & 0x7f) + ((Packet[20] & 0x30) << 3);
			Vy_package = (Packet[15] & 0x80) ? ( -Vy_package ) : Vy_package;
			Vr_package = (Packet[16] & 0x7f) + ((Packet[20] & 0x0f) << 7);
			Vr_package = (Packet[16] & 0x80) ? ( -Vr_package ) : Vr_package;
//			Robot_Is_Report = Packet[13] >> 7;
			Robot_drib = (Packet[13] >> 4) & 0x03;
			Robot_Chip_Or_Shoot = ( Packet[13] >> 6 ) & 0x01;
			Robot_Boot_Power = Packet[24] & 0x7f;
		}
		else
			received_packet_flag = 0;
	}
		else
			received_packet_flag = 0;
};

void pack(uint8_t *TX_Packet){
	memset(TX_Packet, 0, 25);
	TX_Packet[0] = 0xff;
	TX_Packet[1] = 0x02;
	TX_Packet[2] = robot_num + 1;
	TX_Packet[3] = Robot_Status;
}

void motion_planner(void){
	int16_t acc_x = 0;
	int16_t acc_y = 0;
	double acc_whole = 0;
	double sin_x = 0;
	double sin_y = 0;
	acc_x = Vx_package - Vx_package_last;
	acc_y = Vy_package - Vy_package_last;
	acc_whole = acc_x * acc_x + acc_y * acc_y ;
	acc_whole = sqrt(acc_whole);
	sin_x = acc_x / acc_whole;
	sin_y = acc_y / acc_whole;

	if (acc_whole > acc_set)
	{
		acc_whole = acc_set;
		acc_x = acc_whole * sin_x;
		acc_y = acc_whole * sin_y;
		Vx_package = Vx_package_last + acc_x;
		Vy_package = Vy_package_last + acc_y;
	}

	if((Vr_package - Vr_package_last)  >  acc_r_set) Vr_package = Vr_package_last + acc_r_set;
	if((Vr_package - Vr_package_last)  < -acc_r_set) Vr_package = Vr_package_last - acc_r_set;

	Vx_package_last = Vx_package;
	Vy_package_last = Vy_package;
	Vr_package_last = Vr_package;

	Vel_Motor1 = (sin_angle[0] * Vx_package + cos_angle[0] * Vy_package + 0.205 * Vr_package) * Vel_k2; // 0.025*8.2
	Vel_Motor2 = (sin_angle[1] * Vx_package + cos_angle[1] * Vy_package + 0.205 * Vr_package) * Vel_k2;
	Vel_Motor3 = (sin_angle[2] * Vx_package + cos_angle[2] * Vy_package + 0.205 * Vr_package) * Vel_k2;
	Vel_Motor4 = (sin_angle[3] * Vx_package + cos_angle[3] * Vy_package + 0.205 * Vr_package) * Vel_k2;
}
/* USER CODE END 4 */

void Error_Handler(void)
{
}

/************************ (C) COPYRIGHT STMicroelectronics *****END OF FILE****/
